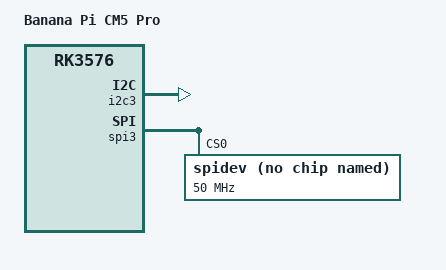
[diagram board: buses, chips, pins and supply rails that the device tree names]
// SPDX-License-Identifier: (GPL-2.0+ OR MIT)

/dts-v1/;

#include "rk3576-armsom-cm5-io.dts"

/ {
	model = "Banana Pi CM5 Pro";
	compatible = "bananapi,bpi-cm5-pro", "armsom,cm5-io", "armsom,cm5", "rockchip,rk3576";
};

&i2c3 {
	pinctrl-names = "default";
	pinctrl-0 = <&i2c3m0_xfer>;
	status = "okay";
};

&spi3 {
	pinctrl-names = "default";
	pinctrl-0 = <&spi3m0_pins &spi3m0_csn0>;
	status = "okay";

	spidev@0 {
		compatible = "rockchip,spidev";
		reg = <0>;
		spi-max-frequency = <50000000>;
		status = "okay";
	};
};
